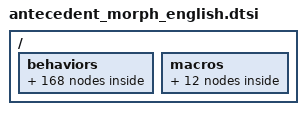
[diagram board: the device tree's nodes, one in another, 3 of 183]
// English schema version v2.0
// Automatically generated by Antecedent Morph Configurator

/ {
    behaviors {
        // Mod-Morphs
        // Base layer
        // NE
        amenneagm: amenneagm {
            compatible = "zmk,behavior-mod-morph";
            #binding-cells = <0>;
            bindings = <&amennea>, <&amenneg>;
            mods = <(MOD_LGUI)>;
        };
        amennecagm: amennecagm {
            compatible = "zmk,behavior-mod-morph";
            #binding-cells = <0>;
            bindings = <&amennec>, <&amenneagm>;
            mods = <(MOD_LALT|MOD_LGUI)>;
        };
        amennem: amennem {
            compatible = "zmk,behavior-mod-morph";
            #binding-cells = <0>;
            bindings = <&amenne>, <&amennecagm>;
            mods = <(MOD_LCTL|MOD_LALT|MOD_LGUI)>;
        };
        // E
        ameneagm: ameneagm {
            compatible = "zmk,behavior-mod-morph";
            #binding-cells = <0>;
            bindings = <&amenea>, <&ameneg>;
            mods = <(MOD_LGUI)>;
        };
        amenecagm: amenecagm {
            compatible = "zmk,behavior-mod-morph";
            #binding-cells = <0>;
            bindings = <&amenec>, <&ameneagm>;
            mods = <(MOD_LALT|MOD_LGUI)>;
        };
        amenem: amenem {
            compatible = "zmk,behavior-mod-morph";
            #binding-cells = <0>;
            bindings = <&amene>, <&amenecagm>;
            mods = <(MOD_LCTL|MOD_LALT|MOD_LGUI)>;
        };
        // SE
        amenseagm: amenseagm {
            compatible = "zmk,behavior-mod-morph";
            #binding-cells = <0>;
            bindings = <&amensea>, <&amenseg>;
            mods = <(MOD_LGUI)>;
        };
        amensecagm: amensecagm {
            compatible = "zmk,behavior-mod-morph";
            #binding-cells = <0>;
            bindings = <&amensec>, <&amenseagm>;
            mods = <(MOD_LALT|MOD_LGUI)>;
        };
        amensem: amensem {
            compatible = "zmk,behavior-mod-morph";
            #binding-cells = <0>;
            bindings = <&amense>, <&amensecagm>;
            mods = <(MOD_LCTL|MOD_LALT|MOD_LGUI)>;
        };
        // NW
        amennwagm: amennwagm {
            compatible = "zmk,behavior-mod-morph";
            #binding-cells = <0>;
            bindings = <&amennwa>, <&amennwg>;
            mods = <(MOD_RGUI)>;
        };
        amennwcagm: amennwcagm {
            compatible = "zmk,behavior-mod-morph";
            #binding-cells = <0>;
            bindings = <&amennwc>, <&amennwagm>;
            mods = <(MOD_RALT|MOD_RGUI)>;
        };
        amennwm: amennwm {
            compatible = "zmk,behavior-mod-morph";
            #binding-cells = <0>;
            bindings = <&amennw>, <&amennwcagm>;
            mods = <(MOD_RCTL|MOD_RALT|MOD_RGUI)>;
        };
        // W
        amenwagm: amenwagm {
            compatible = "zmk,behavior-mod-morph";
            #binding-cells = <0>;
            bindings = <&amenwa>, <&amenwg>;
            mods = <(MOD_RGUI)>;
        };
        amenwcagm: amenwcagm {
            compatible = "zmk,behavior-mod-morph";
            #binding-cells = <0>;
            bindings = <&amenwc>, <&amenwagm>;
            mods = <(MOD_RALT|MOD_RGUI)>;
        };
        amenwm: amenwm {
            compatible = "zmk,behavior-mod-morph";
            #binding-cells = <0>;
            bindings = <&amenw>, <&amenwcagm>;
            mods = <(MOD_RCTL|MOD_RALT|MOD_RGUI)>;
        };
        // SW
        amenswagm: amenswagm {
            compatible = "zmk,behavior-mod-morph";
            #binding-cells = <0>;
            bindings = <&amenswa>, <&amenswg>;
            mods = <(MOD_RGUI)>;
        };
        amenswcagm: amenswcagm {
            compatible = "zmk,behavior-mod-morph";
            #binding-cells = <0>;
            bindings = <&amenswc>, <&amenswagm>;
            mods = <(MOD_RALT|MOD_RGUI)>;
        };
        amenswm: amenswm {
            compatible = "zmk,behavior-mod-morph";
            #binding-cells = <0>;
            bindings = <&amensw>, <&amenswcagm>;
            mods = <(MOD_RCTL|MOD_RALT|MOD_RGUI)>;
        };
        // Mouse layer
        // NE
        amenmosneagm: amenmosneagm {
            compatible = "zmk,behavior-mod-morph";
            #binding-cells = <0>;
            bindings = <&amenmosnea>, <&amenmosneg>;
            mods = <(MOD_LGUI)>;
        };
        amenmosnecagm: amenmosnecagm {
            compatible = "zmk,behavior-mod-morph";
            #binding-cells = <0>;
            bindings = <&amenmosnec>, <&amenmosneagm>;
            mods = <(MOD_LALT|MOD_LGUI)>;
        };
        amenmosnem: amenmosnem {
            compatible = "zmk,behavior-mod-morph";
            #binding-cells = <0>;
            bindings = <&amenmosne>, <&amenmosnecagm>;
            mods = <(MOD_LCTL|MOD_LALT|MOD_LGUI)>;
        };
        // E
        amenmoseagm: amenmoseagm {
            compatible = "zmk,behavior-mod-morph";
            #binding-cells = <0>;
            bindings = <&amenmosea>, <&amenmoseg>;
            mods = <(MOD_LGUI)>;
        };
        amenmosecagm: amenmosecagm {
            compatible = "zmk,behavior-mod-morph";
            #binding-cells = <0>;
            bindings = <&amenmosec>, <&amenmoseagm>;
            mods = <(MOD_LALT|MOD_LGUI)>;
        };
        amenmosem: amenmosem {
            compatible = "zmk,behavior-mod-morph";
            #binding-cells = <0>;
            bindings = <&amenmose>, <&amenmosecagm>;
            mods = <(MOD_LCTL|MOD_LALT|MOD_LGUI)>;
        };
        // SE
        amenmosseagm: amenmosseagm {
            compatible = "zmk,behavior-mod-morph";
            #binding-cells = <0>;
            bindings = <&amenmossea>, <&amenmosseg>;
            mods = <(MOD_LGUI)>;
        };
        amenmossecagm: amenmossecagm {
            compatible = "zmk,behavior-mod-morph";
            #binding-cells = <0>;
            bindings = <&amenmossec>, <&amenmosseagm>;
            mods = <(MOD_LALT|MOD_LGUI)>;
        };
        amenmossem: amenmossem {
            compatible = "zmk,behavior-mod-morph";
            #binding-cells = <0>;
            bindings = <&amenmosse>, <&amenmossecagm>;
            mods = <(MOD_LCTL|MOD_LALT|MOD_LGUI)>;
        };
        // Navigation layer
        // NE
        amennavneagm: amennavneagm {
            compatible = "zmk,behavior-mod-morph";
            #binding-cells = <0>;
            bindings = <&amennavnea>, <&amennavneg>;
            mods = <(MOD_LGUI)>;
        };
        amennavnecagm: amennavnecagm {
            compatible = "zmk,behavior-mod-morph";
            #binding-cells = <0>;
            bindings = <&amennavnec>, <&amennavneagm>;
            mods = <(MOD_LALT|MOD_LGUI)>;
        };
        amennavnem: amennavnem {
            compatible = "zmk,behavior-mod-morph";
            #binding-cells = <0>;
            bindings = <&amennavne>, <&amennavnecagm>;
            mods = <(MOD_LCTL|MOD_LALT|MOD_LGUI)>;
        };
        // E
        amennaveagm: amennaveagm {
            compatible = "zmk,behavior-mod-morph";
            #binding-cells = <0>;
            bindings = <&amennavea>, <&amennaveg>;
            mods = <(MOD_LGUI)>;
        };
        amennavecagm: amennavecagm {
            compatible = "zmk,behavior-mod-morph";
            #binding-cells = <0>;
            bindings = <&amennavec>, <&amennaveagm>;
            mods = <(MOD_LALT|MOD_LGUI)>;
        };
        amennavem: amennavem {
            compatible = "zmk,behavior-mod-morph";
            #binding-cells = <0>;
            bindings = <&amennave>, <&amennavecagm>;
            mods = <(MOD_LCTL|MOD_LALT|MOD_LGUI)>;
        };
        // SE
        amennavseagm: amennavseagm {
            compatible = "zmk,behavior-mod-morph";
            #binding-cells = <0>;
            bindings = <&amennavsea>, <&amennavseg>;
            mods = <(MOD_LGUI)>;
        };
        amennavsecagm: amennavsecagm {
            compatible = "zmk,behavior-mod-morph";
            #binding-cells = <0>;
            bindings = <&amennavsec>, <&amennavseagm>;
            mods = <(MOD_LALT|MOD_LGUI)>;
        };
        amennavsem: amennavsem {
            compatible = "zmk,behavior-mod-morph";
            #binding-cells = <0>;
            bindings = <&amennavse>, <&amennavsecagm>;
            mods = <(MOD_LCTL|MOD_LALT|MOD_LGUI)>;
        };
        // Media layer
        // NE
        amenmedneagm: amenmedneagm {
            compatible = "zmk,behavior-mod-morph";
            #binding-cells = <0>;
            bindings = <&amenmednea>, <&amenmedneg>;
            mods = <(MOD_LGUI)>;
        };
        amenmednecagm: amenmednecagm {
            compatible = "zmk,behavior-mod-morph";
            #binding-cells = <0>;
            bindings = <&amenmednec>, <&amenmedneagm>;
            mods = <(MOD_LALT|MOD_LGUI)>;
        };
        amenmednem: amenmednem {
            compatible = "zmk,behavior-mod-morph";
            #binding-cells = <0>;
            bindings = <&amenmedne>, <&amenmednecagm>;
            mods = <(MOD_LCTL|MOD_LALT|MOD_LGUI)>;
        };
        // E
        amenmedeagm: amenmedeagm {
            compatible = "zmk,behavior-mod-morph";
            #binding-cells = <0>;
            bindings = <&amenmedea>, <&amenmedeg>;
            mods = <(MOD_LGUI)>;
        };
        amenmedecagm: amenmedecagm {
            compatible = "zmk,behavior-mod-morph";
            #binding-cells = <0>;
            bindings = <&amenmedec>, <&amenmedeagm>;
            mods = <(MOD_LALT|MOD_LGUI)>;
        };
        amenmedem: amenmedem {
            compatible = "zmk,behavior-mod-morph";
            #binding-cells = <0>;
            bindings = <&amenmede>, <&amenmedecagm>;
            mods = <(MOD_LCTL|MOD_LALT|MOD_LGUI)>;
        };
        // SE
        amenmedseagm: amenmedseagm {
            compatible = "zmk,behavior-mod-morph";
            #binding-cells = <0>;
            bindings = <&amenmedsea>, <&amenmedseg>;
            mods = <(MOD_LGUI)>;
        };
        amenmedsecagm: amenmedsecagm {
            compatible = "zmk,behavior-mod-morph";
            #binding-cells = <0>;
            bindings = <&amenmedsec>, <&amenmedseagm>;
            mods = <(MOD_LALT|MOD_LGUI)>;
        };
        amenmedsem: amenmedsem {
            compatible = "zmk,behavior-mod-morph";
            #binding-cells = <0>;
            bindings = <&amenmedse>, <&amenmedsecagm>;
            mods = <(MOD_LCTL|MOD_LALT|MOD_LGUI)>;
        };
        // Symbol layer
        // NW
        amensymnwagm: amensymnwagm {
            compatible = "zmk,behavior-mod-morph";
            #binding-cells = <0>;
            bindings = <&amensymnwa>, <&amensymnwg>;
            mods = <(MOD_RGUI)>;
        };
        amensymnwcagm: amensymnwcagm {
            compatible = "zmk,behavior-mod-morph";
            #binding-cells = <0>;
            bindings = <&amensymnwc>, <&amensymnwagm>;
            mods = <(MOD_RALT|MOD_RGUI)>;
        };
        amensymnwm: amensymnwm {
            compatible = "zmk,behavior-mod-morph";
            #binding-cells = <0>;
            bindings = <&amensymnw>, <&amensymnwcagm>;
            mods = <(MOD_RCTL|MOD_RALT|MOD_RGUI)>;
        };
        // W
        amensymwagm: amensymwagm {
            compatible = "zmk,behavior-mod-morph";
            #binding-cells = <0>;
            bindings = <&amensymwa>, <&amensymwg>;
            mods = <(MOD_RGUI)>;
        };
        amensymwcagm: amensymwcagm {
            compatible = "zmk,behavior-mod-morph";
            #binding-cells = <0>;
            bindings = <&amensymwc>, <&amensymwagm>;
            mods = <(MOD_RALT|MOD_RGUI)>;
        };
        amensymwm: amensymwm {
            compatible = "zmk,behavior-mod-morph";
            #binding-cells = <0>;
            bindings = <&amensymw>, <&amensymwcagm>;
            mods = <(MOD_RCTL|MOD_RALT|MOD_RGUI)>;
        };
        // SW
        amensymswagm: amensymswagm {
            compatible = "zmk,behavior-mod-morph";
            #binding-cells = <0>;
            bindings = <&amensymswa>, <&amensymswg>;
            mods = <(MOD_RGUI)>;
        };
        amensymswcagm: amensymswcagm {
            compatible = "zmk,behavior-mod-morph";
            #binding-cells = <0>;
            bindings = <&amensymswc>, <&amensymswagm>;
            mods = <(MOD_RALT|MOD_RGUI)>;
        };
        amensymswm: amensymswm {
            compatible = "zmk,behavior-mod-morph";
            #binding-cells = <0>;
            bindings = <&amensymsw>, <&amensymswcagm>;
            mods = <(MOD_RCTL|MOD_RALT|MOD_RGUI)>;
        };
        // Number layer
        // NW
        amennumnwagm: amennumnwagm {
            compatible = "zmk,behavior-mod-morph";
            #binding-cells = <0>;
            bindings = <&amennumnwa>, <&amennumnwg>;
            mods = <(MOD_RGUI)>;
        };
        amennumnwcagm: amennumnwcagm {
            compatible = "zmk,behavior-mod-morph";
            #binding-cells = <0>;
            bindings = <&amennumnwc>, <&amennumnwagm>;
            mods = <(MOD_RALT|MOD_RGUI)>;
        };
        amennumnwm: amennumnwm {
            compatible = "zmk,behavior-mod-morph";
            #binding-cells = <0>;
            bindings = <&amennumnw>, <&amennumnwcagm>;
            mods = <(MOD_RCTL|MOD_RALT|MOD_RGUI)>;
        };
        // W
        amennumwagm: amennumwagm {
            compatible = "zmk,behavior-mod-morph";
            #binding-cells = <0>;
            bindings = <&amennumwa>, <&amennumwg>;
            mods = <(MOD_RGUI)>;
        };
        amennumwcagm: amennumwcagm {
            compatible = "zmk,behavior-mod-morph";
            #binding-cells = <0>;
            bindings = <&amennumwc>, <&amennumwagm>;
            mods = <(MOD_RALT|MOD_RGUI)>;
        };
        amennumwm: amennumwm {
            compatible = "zmk,behavior-mod-morph";
            #binding-cells = <0>;
            bindings = <&amennumw>, <&amennumwcagm>;
            mods = <(MOD_RCTL|MOD_RALT|MOD_RGUI)>;
        };
        // SW
        amennumswagm: amennumswagm {
            compatible = "zmk,behavior-mod-morph";
            #binding-cells = <0>;
            bindings = <&amennumswa>, <&amennumswg>;
            mods = <(MOD_RGUI)>;
        };
        amennumswcagm: amennumswcagm {
            compatible = "zmk,behavior-mod-morph";
            #binding-cells = <0>;
            bindings = <&amennumswc>, <&amennumswagm>;
            mods = <(MOD_RALT|MOD_RGUI)>;
        };
        amennumswm: amennumswm {
            compatible = "zmk,behavior-mod-morph";
            #binding-cells = <0>;
            bindings = <&amennumsw>, <&amennumswcagm>;
            mods = <(MOD_RCTL|MOD_RALT|MOD_RGUI)>;
        };
        // Function layer
        // NW
        amenfunnwagm: amenfunnwagm {
            compatible = "zmk,behavior-mod-morph";
            #binding-cells = <0>;
            bindings = <&amenfunnwa>, <&amenfunnwg>;
            mods = <(MOD_RGUI)>;
        };
        amenfunnwcagm: amenfunnwcagm {
            compatible = "zmk,behavior-mod-morph";
            #binding-cells = <0>;
            bindings = <&amenfunnwc>, <&amenfunnwagm>;
            mods = <(MOD_RALT|MOD_RGUI)>;
        };
        amenfunnwm: amenfunnwm {
            compatible = "zmk,behavior-mod-morph";
            #binding-cells = <0>;
            bindings = <&amenfunnw>, <&amenfunnwcagm>;
            mods = <(MOD_RCTL|MOD_RALT|MOD_RGUI)>;
        };
        // W
        amenfunwagm: amenfunwagm {
            compatible = "zmk,behavior-mod-morph";
            #binding-cells = <0>;
            bindings = <&amenfunwa>, <&amenfunwg>;
            mods = <(MOD_RGUI)>;
        };
        amenfunwcagm: amenfunwcagm {
            compatible = "zmk,behavior-mod-morph";
            #binding-cells = <0>;
            bindings = <&amenfunwc>, <&amenfunwagm>;
            mods = <(MOD_RALT|MOD_RGUI)>;
        };
        amenfunwm: amenfunwm {
            compatible = "zmk,behavior-mod-morph";
            #binding-cells = <0>;
            bindings = <&amenfunw>, <&amenfunwcagm>;
            mods = <(MOD_RCTL|MOD_RALT|MOD_RGUI)>;
        };
        // SW
        amenfunswagm: amenfunswagm {
            compatible = "zmk,behavior-mod-morph";
            #binding-cells = <0>;
            bindings = <&amenfunswa>, <&amenfunswg>;
            mods = <(MOD_RGUI)>;
        };
        amenfunswcagm: amenfunswcagm {
            compatible = "zmk,behavior-mod-morph";
            #binding-cells = <0>;
            bindings = <&amenfunswc>, <&amenfunswagm>;
            mods = <(MOD_RALT|MOD_RGUI)>;
        };
        amenfunswm: amenfunswm {
            compatible = "zmk,behavior-mod-morph";
            #binding-cells = <0>;
            bindings = <&amenfunsw>, <&amenfunswcagm>;
            mods = <(MOD_RCTL|MOD_RALT|MOD_RGUI)>;
        };
        // Antecedent Morphs
        amenne: am_en_ne {
            compatible = "zmk,behavior-antecedent-morph";
            label = "AM_EN_NE";
            #binding-cells = <0>;
            defaults = <&none>;
            bindings = <&amen_prokofyevme>;
            antecedents = <AT>;
            max-delay-ms = <U_ANTMORPH_DELAY>;
        };
        amennec: am_en_ne_c {
            compatible = "zmk,behavior-antecedent-morph";
            label = "AM_EN_NE_C";
            #binding-cells = <0>;
            defaults = <&none>;
            bindings = <&none>;
            antecedents = <0x070100>;
            max-delay-ms = <U_ANTMORPH_DELAY>;
        };
        amennea: am_en_ne_a {
            compatible = "zmk,behavior-antecedent-morph";
            label = "AM_EN_NE_A";
            #binding-cells = <0>;
            defaults = <&none>;
            bindings = <&none>;
            antecedents = <0x070100>;
            max-delay-ms = <U_ANTMORPH_DELAY>;
        };
        amenneg: am_en_ne_g {
            compatible = "zmk,behavior-antecedent-morph";
            label = "AM_EN_NE_G";
            #binding-cells = <0>;
            defaults = <&none>;
            bindings = <&none>;
            antecedents = <0x070100>;
            max-delay-ms = <U_ANTMORPH_DELAY>;
        };
        amene: am_en_e {
            compatible = "zmk,behavior-antecedent-morph";
            label = "AM_EN_E";
            #binding-cells = <0>;
            defaults = <&none>;
            bindings = <&amen_proostas>, <&amen_monday>, <&amen_tuesday>, <&amen_wednesday>, <&amen_thursday>, <&amen_friday>, <&amen_saturday>, <&amen_sunday>, <&amen_yandexru>, <&amen_english_v20>;
            antecedents = <P N1 N2 N3 N4 N5 N6 N7 AT SPACE>;
            max-delay-ms = <U_ANTMORPH_DELAY>;
        };
        amenec: am_en_e_c {
            compatible = "zmk,behavior-antecedent-morph";
            label = "AM_EN_E_C";
            #binding-cells = <0>;
            defaults = <&none>;
            bindings = <&none>;
            antecedents = <0x070100>;
            max-delay-ms = <U_ANTMORPH_DELAY>;
        };
        amenea: am_en_e_a {
            compatible = "zmk,behavior-antecedent-morph";
            label = "AM_EN_E_A";
            #binding-cells = <0>;
            defaults = <&none>;
            bindings = <&none>;
            antecedents = <0x070100>;
            max-delay-ms = <U_ANTMORPH_DELAY>;
        };
        ameneg: am_en_e_g {
            compatible = "zmk,behavior-antecedent-morph";
            label = "AM_EN_E_G";
            #binding-cells = <0>;
            defaults = <&none>;
            bindings = <&none>;
            antecedents = <0x070100>;
            max-delay-ms = <U_ANTMORPH_DELAY>;
        };
        amense: am_en_se {
            compatible = "zmk,behavior-antecedent-morph";
            label = "AM_EN_SE";
            #binding-cells = <0>;
            defaults = <&none>;
            bindings = <&amen_gmailcom>;
            antecedents = <AT>;
            max-delay-ms = <U_ANTMORPH_DELAY>;
        };
        amensec: am_en_se_c {
            compatible = "zmk,behavior-antecedent-morph";
            label = "AM_EN_SE_C";
            #binding-cells = <0>;
            defaults = <&none>;
            bindings = <&none>;
            antecedents = <0x070100>;
            max-delay-ms = <U_ANTMORPH_DELAY>;
        };
        amensea: am_en_se_a {
            compatible = "zmk,behavior-antecedent-morph";
            label = "AM_EN_SE_A";
            #binding-cells = <0>;
            defaults = <&none>;
            bindings = <&none>;
            antecedents = <0x070100>;
            max-delay-ms = <U_ANTMORPH_DELAY>;
        };
        amenseg: am_en_se_g {
            compatible = "zmk,behavior-antecedent-morph";
            label = "AM_EN_SE_G";
            #binding-cells = <0>;
            defaults = <&none>;
            bindings = <&none>;
            antecedents = <0x070100>;
            max-delay-ms = <U_ANTMORPH_DELAY>;
        };
        amennw: am_en_nw {
            compatible = "zmk,behavior-antecedent-morph";
            label = "AM_EN_NW";
            #binding-cells = <0>;
            defaults = <&none>;
            bindings = <&none>;
            antecedents = <0x070100>;
            max-delay-ms = <U_ANTMORPH_DELAY>;
        };
        amennwc: am_en_nw_c {
            compatible = "zmk,behavior-antecedent-morph";
            label = "AM_EN_NW_C";
            #binding-cells = <0>;
            defaults = <&none>;
            bindings = <&none>;
            antecedents = <0x070100>;
            max-delay-ms = <U_ANTMORPH_DELAY>;
        };
        amennwa: am_en_nw_a {
            compatible = "zmk,behavior-antecedent-morph";
            label = "AM_EN_NW_A";
            #binding-cells = <0>;
            defaults = <&none>;
            bindings = <&none>;
            antecedents = <0x070100>;
            max-delay-ms = <U_ANTMORPH_DELAY>;
        };
        amennwg: am_en_nw_g {
            compatible = "zmk,behavior-antecedent-morph";
            label = "AM_EN_NW_G";
            #binding-cells = <0>;
            defaults = <&none>;
            bindings = <&none>;
            antecedents = <0x070100>;
            max-delay-ms = <U_ANTMORPH_DELAY>;
        };
        amenw: am_en_w {
            compatible = "zmk,behavior-antecedent-morph";
            label = "AM_EN_W";
            #binding-cells = <0>;
            defaults = <&none>;
            bindings = <&none>;
            antecedents = <0x070100>;
            max-delay-ms = <U_ANTMORPH_DELAY>;
        };
        amenwc: am_en_w_c {
            compatible = "zmk,behavior-antecedent-morph";
            label = "AM_EN_W_C";
            #binding-cells = <0>;
            defaults = <&none>;
            bindings = <&none>;
            antecedents = <0x070100>;
            max-delay-ms = <U_ANTMORPH_DELAY>;
        };
        amenwa: am_en_w_a {
            compatible = "zmk,behavior-antecedent-morph";
            label = "AM_EN_W_A";
            #binding-cells = <0>;
            defaults = <&none>;
            bindings = <&none>;
            antecedents = <0x070100>;
            max-delay-ms = <U_ANTMORPH_DELAY>;
        };
        amenwg: am_en_w_g {
            compatible = "zmk,behavior-antecedent-morph";
            label = "AM_EN_W_G";
            #binding-cells = <0>;
            defaults = <&none>;
            bindings = <&none>;
            antecedents = <0x070100>;
            max-delay-ms = <U_ANTMORPH_DELAY>;
        };
        amensw: am_en_sw {
            compatible = "zmk,behavior-antecedent-morph";
            label = "AM_EN_SW";
            #binding-cells = <0>;
            defaults = <&none>;
            bindings = <&none>;
            antecedents = <0x070100>;
            max-delay-ms = <U_ANTMORPH_DELAY>;
        };
        amenswc: am_en_sw_c {
            compatible = "zmk,behavior-antecedent-morph";
            label = "AM_EN_SW_C";
            #binding-cells = <0>;
            defaults = <&none>;
            bindings = <&none>;
            antecedents = <0x070100>;
            max-delay-ms = <U_ANTMORPH_DELAY>;
        };
        amenswa: am_en_sw_a {
            compatible = "zmk,behavior-antecedent-morph";
            label = "AM_EN_SW_A";
            #binding-cells = <0>;
            defaults = <&none>;
            bindings = <&none>;
            antecedents = <0x070100>;
            max-delay-ms = <U_ANTMORPH_DELAY>;
        };
        amenswg: am_en_sw_g {
            compatible = "zmk,behavior-antecedent-morph";
            label = "AM_EN_SW_G";
            #binding-cells = <0>;
            defaults = <&none>;
            bindings = <&none>;
            antecedents = <0x070100>;
            max-delay-ms = <U_ANTMORPH_DELAY>;
        };
        amenmosne: am_en_mos_ne {
            compatible = "zmk,behavior-antecedent-morph";
            label = "AM_EN_MOS_NE";
            #binding-cells = <0>;
            defaults = <&none>;
            bindings = <&none>;
            antecedents = <0x070100>;
            max-delay-ms = <U_ANTMORPH_DELAY>;
        };
        amenmosnec: am_en_mos_ne_c {
            compatible = "zmk,behavior-antecedent-morph";
            label = "AM_EN_MOS_NE_C";
            #binding-cells = <0>;
            defaults = <&none>;
            bindings = <&none>;
            antecedents = <0x070100>;
            max-delay-ms = <U_ANTMORPH_DELAY>;
        };
        amenmosnea: am_en_mos_ne_a {
            compatible = "zmk,behavior-antecedent-morph";
            label = "AM_EN_MOS_NE_A";
            #binding-cells = <0>;
            defaults = <&none>;
            bindings = <&none>;
            antecedents = <0x070100>;
            max-delay-ms = <U_ANTMORPH_DELAY>;
        };
        amenmosneg: am_en_mos_ne_g {
            compatible = "zmk,behavior-antecedent-morph";
            label = "AM_EN_MOS_NE_G";
            #binding-cells = <0>;
            defaults = <&none>;
            bindings = <&none>;
            antecedents = <0x070100>;
            max-delay-ms = <U_ANTMORPH_DELAY>;
        };
        amenmose: am_en_mos_e {
            compatible = "zmk,behavior-antecedent-morph";
            label = "AM_EN_MOS_E";
            #binding-cells = <0>;
            defaults = <&none>;
            bindings = <&none>;
            antecedents = <0x070100>;
            max-delay-ms = <U_ANTMORPH_DELAY>;
        };
        amenmosec: am_en_mos_e_c {
            compatible = "zmk,behavior-antecedent-morph";
            label = "AM_EN_MOS_E_C";
            #binding-cells = <0>;
            defaults = <&none>;
            bindings = <&none>;
            antecedents = <0x070100>;
            max-delay-ms = <U_ANTMORPH_DELAY>;
        };
        amenmosea: am_en_mos_e_a {
            compatible = "zmk,behavior-antecedent-morph";
            label = "AM_EN_MOS_E_A";
            #binding-cells = <0>;
            defaults = <&none>;
            bindings = <&none>;
            antecedents = <0x070100>;
            max-delay-ms = <U_ANTMORPH_DELAY>;
        };
        amenmoseg: am_en_mos_e_g {
            compatible = "zmk,behavior-antecedent-morph";
            label = "AM_EN_MOS_E_G";
            #binding-cells = <0>;
            defaults = <&none>;
            bindings = <&none>;
            antecedents = <0x070100>;
            max-delay-ms = <U_ANTMORPH_DELAY>;
        };
        amenmosse: am_en_mos_se {
            compatible = "zmk,behavior-antecedent-morph";
            label = "AM_EN_MOS_SE";
            #binding-cells = <0>;
            defaults = <&none>;
            bindings = <&none>;
            antecedents = <0x070100>;
            max-delay-ms = <U_ANTMORPH_DELAY>;
        };
        amenmossec: am_en_mos_se_c {
            compatible = "zmk,behavior-antecedent-morph";
            label = "AM_EN_MOS_SE_C";
            #binding-cells = <0>;
            defaults = <&none>;
            bindings = <&none>;
            antecedents = <0x070100>;
            max-delay-ms = <U_ANTMORPH_DELAY>;
        };
        amenmossea: am_en_mos_se_a {
            compatible = "zmk,behavior-antecedent-morph";
            label = "AM_EN_MOS_SE_A";
            #binding-cells = <0>;
            defaults = <&none>;
            bindings = <&none>;
            antecedents = <0x070100>;
            max-delay-ms = <U_ANTMORPH_DELAY>;
        };
        amenmosseg: am_en_mos_se_g {
            compatible = "zmk,behavior-antecedent-morph";
            label = "AM_EN_MOS_SE_G";
            #binding-cells = <0>;
            defaults = <&none>;
            bindings = <&none>;
            antecedents = <0x070100>;
            max-delay-ms = <U_ANTMORPH_DELAY>;
        };
        amennavne: am_en_nav_ne {
            compatible = "zmk,behavior-antecedent-morph";
            label = "AM_EN_NAV_NE";
            #binding-cells = <0>;
            defaults = <&none>;
            bindings = <&none>;
            antecedents = <0x070100>;
            max-delay-ms = <U_ANTMORPH_DELAY>;
        };
        amennavnec: am_en_nav_ne_c {
            compatible = "zmk,behavior-antecedent-morph";
            label = "AM_EN_NAV_NE_C";
            #binding-cells = <0>;
            defaults = <&none>;
            bindings = <&none>;
            antecedents = <0x070100>;
            max-delay-ms = <U_ANTMORPH_DELAY>;
        };
        amennavnea: am_en_nav_ne_a {
            compatible = "zmk,behavior-antecedent-morph";
            label = "AM_EN_NAV_NE_A";
            #binding-cells = <0>;
            defaults = <&none>;
            bindings = <&none>;
            antecedents = <0x070100>;
            max-delay-ms = <U_ANTMORPH_DELAY>;
        };
        amennavneg: am_en_nav_ne_g {
            compatible = "zmk,behavior-antecedent-morph";
            label = "AM_EN_NAV_NE_G";
            #binding-cells = <0>;
            defaults = <&none>;
            bindings = <&none>;
            antecedents = <0x070100>;
            max-delay-ms = <U_ANTMORPH_DELAY>;
        };
        amennave: am_en_nav_e {
            compatible = "zmk,behavior-antecedent-morph";
            label = "AM_EN_NAV_E";
            #binding-cells = <0>;
            defaults = <&none>;
            bindings = <&none>;
            antecedents = <0x070100>;
            max-delay-ms = <U_ANTMORPH_DELAY>;
        };
        amennavec: am_en_nav_e_c {
            compatible = "zmk,behavior-antecedent-morph";
            label = "AM_EN_NAV_E_C";
            #binding-cells = <0>;
            defaults = <&none>;
            bindings = <&none>;
            antecedents = <0x070100>;
            max-delay-ms = <U_ANTMORPH_DELAY>;
        };
        amennavea: am_en_nav_e_a {
            compatible = "zmk,behavior-antecedent-morph";
            label = "AM_EN_NAV_E_A";
            #binding-cells = <0>;
            defaults = <&none>;
            bindings = <&none>;
            antecedents = <0x070100>;
            max-delay-ms = <U_ANTMORPH_DELAY>;
        };
        amennaveg: am_en_nav_e_g {
            compatible = "zmk,behavior-antecedent-morph";
            label = "AM_EN_NAV_E_G";
            #binding-cells = <0>;
            defaults = <&none>;
            bindings = <&none>;
            antecedents = <0x070100>;
            max-delay-ms = <U_ANTMORPH_DELAY>;
        };
        amennavse: am_en_nav_se {
            compatible = "zmk,behavior-antecedent-morph";
            label = "AM_EN_NAV_SE";
            #binding-cells = <0>;
            defaults = <&none>;
            bindings = <&none>;
            antecedents = <0x070100>;
            max-delay-ms = <U_ANTMORPH_DELAY>;
        };
        amennavsec: am_en_nav_se_c {
            compatible = "zmk,behavior-antecedent-morph";
            label = "AM_EN_NAV_SE_C";
            #binding-cells = <0>;
            defaults = <&none>;
            bindings = <&none>;
            antecedents = <0x070100>;
            max-delay-ms = <U_ANTMORPH_DELAY>;
        };
        amennavsea: am_en_nav_se_a {
            compatible = "zmk,behavior-antecedent-morph";
            label = "AM_EN_NAV_SE_A";
            #binding-cells = <0>;
            defaults = <&none>;
            bindings = <&none>;
            antecedents = <0x070100>;
            max-delay-ms = <U_ANTMORPH_DELAY>;
        };
        amennavseg: am_en_nav_se_g {
            compatible = "zmk,behavior-antecedent-morph";
            label = "AM_EN_NAV_SE_G";
            #binding-cells = <0>;
            defaults = <&none>;
            bindings = <&none>;
            antecedents = <0x070100>;
            max-delay-ms = <U_ANTMORPH_DELAY>;
        };
        amenmedne: am_en_med_ne {
            compatible = "zmk,behavior-antecedent-morph";
            label = "AM_EN_MED_NE";
            #binding-cells = <0>;
            defaults = <&none>;
            bindings = <&none>;
            antecedents = <0x070100>;
            max-delay-ms = <U_ANTMORPH_DELAY>;
        };
        amenmednec: am_en_med_ne_c {
            compatible = "zmk,behavior-antecedent-morph";
            label = "AM_EN_MED_NE_C";
            #binding-cells = <0>;
            defaults = <&none>;
            bindings = <&none>;
            antecedents = <0x070100>;
            max-delay-ms = <U_ANTMORPH_DELAY>;
        };
        amenmednea: am_en_med_ne_a {
            compatible = "zmk,behavior-antecedent-morph";
            label = "AM_EN_MED_NE_A";
            #binding-cells = <0>;
            defaults = <&none>;
            bindings = <&none>;
            antecedents = <0x070100>;
            max-delay-ms = <U_ANTMORPH_DELAY>;
        };
        amenmedneg: am_en_med_ne_g {
            compatible = "zmk,behavior-antecedent-morph";
            label = "AM_EN_MED_NE_G";
            #binding-cells = <0>;
            defaults = <&none>;
            bindings = <&none>;
            antecedents = <0x070100>;
            max-delay-ms = <U_ANTMORPH_DELAY>;
        };
        amenmede: am_en_med_e {
            compatible = "zmk,behavior-antecedent-morph";
            label = "AM_EN_MED_E";
            #binding-cells = <0>;
            defaults = <&none>;
            bindings = <&none>;
            antecedents = <0x070100>;
            max-delay-ms = <U_ANTMORPH_DELAY>;
        };
        amenmedec: am_en_med_e_c {
            compatible = "zmk,behavior-antecedent-morph";
            label = "AM_EN_MED_E_C";
            #binding-cells = <0>;
            defaults = <&none>;
            bindings = <&none>;
            antecedents = <0x070100>;
            max-delay-ms = <U_ANTMORPH_DELAY>;
        };
        amenmedea: am_en_med_e_a {
            compatible = "zmk,behavior-antecedent-morph";
            label = "AM_EN_MED_E_A";
            #binding-cells = <0>;
            defaults = <&none>;
            bindings = <&none>;
            antecedents = <0x070100>;
            max-delay-ms = <U_ANTMORPH_DELAY>;
        };
        amenmedeg: am_en_med_e_g {
            compatible = "zmk,behavior-antecedent-morph";
            label = "AM_EN_MED_E_G";
            #binding-cells = <0>;
            defaults = <&none>;
            bindings = <&none>;
            antecedents = <0x070100>;
            max-delay-ms = <U_ANTMORPH_DELAY>;
        };
        amenmedse: am_en_med_se {
            compatible = "zmk,behavior-antecedent-morph";
            label = "AM_EN_MED_SE";
            #binding-cells = <0>;
            defaults = <&none>;
            bindings = <&none>;
            antecedents = <0x070100>;
            max-delay-ms = <U_ANTMORPH_DELAY>;
        };
        amenmedsec: am_en_med_se_c {
            compatible = "zmk,behavior-antecedent-morph";
            label = "AM_EN_MED_SE_C";
            #binding-cells = <0>;
            defaults = <&none>;
            bindings = <&none>;
            antecedents = <0x070100>;
            max-delay-ms = <U_ANTMORPH_DELAY>;
        };
        amenmedsea: am_en_med_se_a {
            compatible = "zmk,behavior-antecedent-morph";
            label = "AM_EN_MED_SE_A";
            #binding-cells = <0>;
            defaults = <&none>;
            bindings = <&none>;
            antecedents = <0x070100>;
            max-delay-ms = <U_ANTMORPH_DELAY>;
        };
        amenmedseg: am_en_med_se_g {
            compatible = "zmk,behavior-antecedent-morph";
            label = "AM_EN_MED_SE_G";
            #binding-cells = <0>;
            defaults = <&none>;
            bindings = <&none>;
            antecedents = <0x070100>;
            max-delay-ms = <U_ANTMORPH_DELAY>;
        };
        amenfunnw: am_en_fun_nw {
            compatible = "zmk,behavior-antecedent-morph";
            label = "AM_EN_FUN_NW";
            #binding-cells = <0>;
            defaults = <&none>;
            bindings = <&none>;
            antecedents = <0x070100>;
            max-delay-ms = <U_ANTMORPH_DELAY>;
        };
        amenfunnwc: am_en_fun_nw_c {
            compatible = "zmk,behavior-antecedent-morph";
            label = "AM_EN_FUN_NW_C";
            #binding-cells = <0>;
            defaults = <&none>;
            bindings = <&none>;
            antecedents = <0x070100>;
            max-delay-ms = <U_ANTMORPH_DELAY>;
        };
        amenfunnwa: am_en_fun_nw_a {
            compatible = "zmk,behavior-antecedent-morph";
            label = "AM_EN_FUN_NW_A";
            #binding-cells = <0>;
            defaults = <&none>;
            bindings = <&none>;
            antecedents = <0x070100>;
            max-delay-ms = <U_ANTMORPH_DELAY>;
        };
        amenfunnwg: am_en_fun_nw_g {
            compatible = "zmk,behavior-antecedent-morph";
            label = "AM_EN_FUN_NW_G";
            #binding-cells = <0>;
            defaults = <&none>;
            bindings = <&none>;
            antecedents = <0x070100>;
            max-delay-ms = <U_ANTMORPH_DELAY>;
        };
        amenfunw: am_en_fun_w {
            compatible = "zmk,behavior-antecedent-morph";
            label = "AM_EN_FUN_W";
            #binding-cells = <0>;
            defaults = <&none>;
            bindings = <&none>;
            antecedents = <0x070100>;
            max-delay-ms = <U_ANTMORPH_DELAY>;
        };
        amenfunwc: am_en_fun_w_c {
            compatible = "zmk,behavior-antecedent-morph";
            label = "AM_EN_FUN_W_C";
            #binding-cells = <0>;
            defaults = <&none>;
            bindings = <&none>;
            antecedents = <0x070100>;
            max-delay-ms = <U_ANTMORPH_DELAY>;
        };
        amenfunwa: am_en_fun_w_a {
            compatible = "zmk,behavior-antecedent-morph";
            label = "AM_EN_FUN_W_A";
            #binding-cells = <0>;
            defaults = <&none>;
            bindings = <&none>;
            antecedents = <0x070100>;
            max-delay-ms = <U_ANTMORPH_DELAY>;
        };
        amenfunwg: am_en_fun_w_g {
            compatible = "zmk,behavior-antecedent-morph";
            label = "AM_EN_FUN_W_G";
            #binding-cells = <0>;
            defaults = <&none>;
            bindings = <&none>;
            antecedents = <0x070100>;
            max-delay-ms = <U_ANTMORPH_DELAY>;
        };
        amenfunsw: am_en_fun_sw {
            compatible = "zmk,behavior-antecedent-morph";
            label = "AM_EN_FUN_SW";
            #binding-cells = <0>;
            defaults = <&none>;
            bindings = <&none>;
            antecedents = <0x070100>;
            max-delay-ms = <U_ANTMORPH_DELAY>;
        };
        amenfunswc: am_en_fun_sw_c {
            compatible = "zmk,behavior-antecedent-morph";
            label = "AM_EN_FUN_SW_C";
            #binding-cells = <0>;
            defaults = <&none>;
            bindings = <&none>;
            antecedents = <0x070100>;
            max-delay-ms = <U_ANTMORPH_DELAY>;
        };
        amenfunswa: am_en_fun_sw_a {
            compatible = "zmk,behavior-antecedent-morph";
            label = "AM_EN_FUN_SW_A";
            #binding-cells = <0>;
            defaults = <&none>;
            bindings = <&none>;
            antecedents = <0x070100>;
            max-delay-ms = <U_ANTMORPH_DELAY>;
        };
        amenfunswg: am_en_fun_sw_g {
            compatible = "zmk,behavior-antecedent-morph";
            label = "AM_EN_FUN_SW_G";
            #binding-cells = <0>;
            defaults = <&none>;
            bindings = <&none>;
            antecedents = <0x070100>;
            max-delay-ms = <U_ANTMORPH_DELAY>;
        };
        amennumnw: am_en_num_nw {
            compatible = "zmk,behavior-antecedent-morph";
            label = "AM_EN_NUM_NW";
            #binding-cells = <0>;
            defaults = <&none>;
            bindings = <&none>;
            antecedents = <0x070100>;
            max-delay-ms = <U_ANTMORPH_DELAY>;
        };
        amennumnwc: am_en_num_nw_c {
            compatible = "zmk,behavior-antecedent-morph";
            label = "AM_EN_NUM_NW_C";
            #binding-cells = <0>;
            defaults = <&none>;
            bindings = <&none>;
            antecedents = <0x070100>;
            max-delay-ms = <U_ANTMORPH_DELAY>;
        };
        amennumnwa: am_en_num_nw_a {
            compatible = "zmk,behavior-antecedent-morph";
            label = "AM_EN_NUM_NW_A";
            #binding-cells = <0>;
            defaults = <&none>;
            bindings = <&none>;
            antecedents = <0x070100>;
            max-delay-ms = <U_ANTMORPH_DELAY>;
        };
        amennumnwg: am_en_num_nw_g {
            compatible = "zmk,behavior-antecedent-morph";
            label = "AM_EN_NUM_NW_G";
            #binding-cells = <0>;
            defaults = <&none>;
            bindings = <&none>;
            antecedents = <0x070100>;
            max-delay-ms = <U_ANTMORPH_DELAY>;
        };
        amennumw: am_en_num_w {
            compatible = "zmk,behavior-antecedent-morph";
            label = "AM_EN_NUM_W";
            #binding-cells = <0>;
            defaults = <&none>;
            bindings = <&none>;
            antecedents = <0x070100>;
            max-delay-ms = <U_ANTMORPH_DELAY>;
        };
        amennumwc: am_en_num_w_c {
            compatible = "zmk,behavior-antecedent-morph";
            label = "AM_EN_NUM_W_C";
            #binding-cells = <0>;
            defaults = <&none>;
            bindings = <&none>;
            antecedents = <0x070100>;
            max-delay-ms = <U_ANTMORPH_DELAY>;
        };
        amennumwa: am_en_num_w_a {
            compatible = "zmk,behavior-antecedent-morph";
            label = "AM_EN_NUM_W_A";
            #binding-cells = <0>;
            defaults = <&none>;
            bindings = <&none>;
            antecedents = <0x070100>;
            max-delay-ms = <U_ANTMORPH_DELAY>;
        };
        amennumwg: am_en_num_w_g {
            compatible = "zmk,behavior-antecedent-morph";
            label = "AM_EN_NUM_W_G";
            #binding-cells = <0>;
            defaults = <&none>;
            bindings = <&none>;
            antecedents = <0x070100>;
            max-delay-ms = <U_ANTMORPH_DELAY>;
        };
        amennumsw: am_en_num_sw {
            compatible = "zmk,behavior-antecedent-morph";
            label = "AM_EN_NUM_SW";
            #binding-cells = <0>;
            defaults = <&none>;
            bindings = <&none>;
            antecedents = <0x070100>;
            max-delay-ms = <U_ANTMORPH_DELAY>;
        };
        amennumswc: am_en_num_sw_c {
            compatible = "zmk,behavior-antecedent-morph";
            label = "AM_EN_NUM_SW_C";
            #binding-cells = <0>;
            defaults = <&none>;
            bindings = <&none>;
            antecedents = <0x070100>;
            max-delay-ms = <U_ANTMORPH_DELAY>;
        };
        amennumswa: am_en_num_sw_a {
            compatible = "zmk,behavior-antecedent-morph";
            label = "AM_EN_NUM_SW_A";
            #binding-cells = <0>;
            defaults = <&none>;
            bindings = <&none>;
            antecedents = <0x070100>;
            max-delay-ms = <U_ANTMORPH_DELAY>;
        };
        amennumswg: am_en_num_sw_g {
            compatible = "zmk,behavior-antecedent-morph";
            label = "AM_EN_NUM_SW_G";
            #binding-cells = <0>;
            defaults = <&none>;
            bindings = <&none>;
            antecedents = <0x070100>;
            max-delay-ms = <U_ANTMORPH_DELAY>;
        };
        amensymnw: am_en_sym_nw {
            compatible = "zmk,behavior-antecedent-morph";
            label = "AM_EN_SYM_NW";
            #binding-cells = <0>;
            defaults = <&none>;
            bindings = <&none>;
            antecedents = <0x070100>;
            max-delay-ms = <U_ANTMORPH_DELAY>;
        };
        amensymnwc: am_en_sym_nw_c {
            compatible = "zmk,behavior-antecedent-morph";
            label = "AM_EN_SYM_NW_C";
            #binding-cells = <0>;
            defaults = <&none>;
            bindings = <&none>;
            antecedents = <0x070100>;
            max-delay-ms = <U_ANTMORPH_DELAY>;
        };
        amensymnwa: am_en_sym_nw_a {
            compatible = "zmk,behavior-antecedent-morph";
            label = "AM_EN_SYM_NW_A";
            #binding-cells = <0>;
            defaults = <&none>;
            bindings = <&none>;
            antecedents = <0x070100>;
            max-delay-ms = <U_ANTMORPH_DELAY>;
        };
        amensymnwg: am_en_sym_nw_g {
            compatible = "zmk,behavior-antecedent-morph";
            label = "AM_EN_SYM_NW_G";
            #binding-cells = <0>;
            defaults = <&none>;
            bindings = <&none>;
            antecedents = <0x070100>;
            max-delay-ms = <U_ANTMORPH_DELAY>;
        };
        amensymw: am_en_sym_w {
            compatible = "zmk,behavior-antecedent-morph";
            label = "AM_EN_SYM_W";
            #binding-cells = <0>;
            defaults = <&none>;
            bindings = <&none>;
            antecedents = <0x070100>;
            max-delay-ms = <U_ANTMORPH_DELAY>;
        };
        amensymwc: am_en_sym_w_c {
            compatible = "zmk,behavior-antecedent-morph";
            label = "AM_EN_SYM_W_C";
            #binding-cells = <0>;
            defaults = <&none>;
            bindings = <&none>;
            antecedents = <0x070100>;
            max-delay-ms = <U_ANTMORPH_DELAY>;
        };
        amensymwa: am_en_sym_w_a {
            compatible = "zmk,behavior-antecedent-morph";
            label = "AM_EN_SYM_W_A";
            #binding-cells = <0>;
            defaults = <&none>;
            bindings = <&none>;
            antecedents = <0x070100>;
            max-delay-ms = <U_ANTMORPH_DELAY>;
        };
        amensymwg: am_en_sym_w_g {
            compatible = "zmk,behavior-antecedent-morph";
            label = "AM_EN_SYM_W_G";
            #binding-cells = <0>;
            defaults = <&none>;
            bindings = <&none>;
            antecedents = <0x070100>;
            max-delay-ms = <U_ANTMORPH_DELAY>;
        };
        amensymsw: am_en_sym_sw {
            compatible = "zmk,behavior-antecedent-morph";
            label = "AM_EN_SYM_SW";
            #binding-cells = <0>;
            defaults = <&none>;
            bindings = <&none>;
            antecedents = <0x070100>;
            max-delay-ms = <U_ANTMORPH_DELAY>;
        };
        amensymswc: am_en_sym_sw_c {
            compatible = "zmk,behavior-antecedent-morph";
            label = "AM_EN_SYM_SW_C";
            #binding-cells = <0>;
            defaults = <&none>;
            bindings = <&none>;
            antecedents = <0x070100>;
            max-delay-ms = <U_ANTMORPH_DELAY>;
        };
        amensymswa: am_en_sym_sw_a {
            compatible = "zmk,behavior-antecedent-morph";
            label = "AM_EN_SYM_SW_A";
            #binding-cells = <0>;
            defaults = <&none>;
            bindings = <&none>;
            antecedents = <0x070100>;
            max-delay-ms = <U_ANTMORPH_DELAY>;
        };
        amensymswg: am_en_sym_sw_g {
            compatible = "zmk,behavior-antecedent-morph";
            label = "AM_EN_SYM_SW_G";
            #binding-cells = <0>;
            defaults = <&none>;
            bindings = <&none>;
            antecedents = <0x070100>;
            max-delay-ms = <U_ANTMORPH_DELAY>;
        };
    };
    macros {
        // 'P'
        amen_proostas: amen_proostas {
            compatible = "zmk,behavior-macro";
            #binding-cells = <0>;
            wait-ms = <U_ANTMORPH_MACRO_WAIT>;
            tap-ms = <U_ANTMORPH_MACRO_TAP>;
            // (p)roostas
            bindings = <&macro_tap &kp R &kp O &kp O &kp S &kp T &kp A &kp S>;
        };
        // '1'
        amen_monday: amen_monday {
            compatible = "zmk,behavior-macro";
            #binding-cells = <0>;
            wait-ms = <U_ANTMORPH_MACRO_WAIT>;
            tap-ms = <U_ANTMORPH_MACRO_TAP>;
            // [1]Monday
            bindings = <&macro_tap &kp BSPC &kp LS(M) &kp O &kp N &kp D &kp A &kp Y>;
        };
        // '2'
        amen_tuesday: amen_tuesday {
            compatible = "zmk,behavior-macro";
            #binding-cells = <0>;
            wait-ms = <U_ANTMORPH_MACRO_WAIT>;
            tap-ms = <U_ANTMORPH_MACRO_TAP>;
            // [2]Tuesday
            bindings = <&macro_tap &kp BSPC &kp LS(T) &kp U &kp E &kp S &kp D &kp A &kp Y>;
        };
        // '3'
        amen_wednesday: amen_wednesday {
            compatible = "zmk,behavior-macro";
            #binding-cells = <0>;
            wait-ms = <U_ANTMORPH_MACRO_WAIT>;
            tap-ms = <U_ANTMORPH_MACRO_TAP>;
            // [3]Wednesday
            bindings = <&macro_tap &kp BSPC &kp LS(W) &kp E &kp D &kp N &kp E &kp S &kp D &kp A &kp Y>;
        };
        // '4'
        amen_thursday: amen_thursday {
            compatible = "zmk,behavior-macro";
            #binding-cells = <0>;
            wait-ms = <U_ANTMORPH_MACRO_WAIT>;
            tap-ms = <U_ANTMORPH_MACRO_TAP>;
            // [4]Thursday
            bindings = <&macro_tap &kp BSPC &kp LS(T) &kp H &kp U &kp R &kp S &kp D &kp A &kp Y>;
        };
        // '5'
        amen_friday: amen_friday {
            compatible = "zmk,behavior-macro";
            #binding-cells = <0>;
            wait-ms = <U_ANTMORPH_MACRO_WAIT>;
            tap-ms = <U_ANTMORPH_MACRO_TAP>;
            // [5]Friday
            bindings = <&macro_tap &kp BSPC &kp LS(F) &kp R &kp I &kp D &kp A &kp Y>;
        };
        // '6'
        amen_saturday: amen_saturday {
            compatible = "zmk,behavior-macro";
            #binding-cells = <0>;
            wait-ms = <U_ANTMORPH_MACRO_WAIT>;
            tap-ms = <U_ANTMORPH_MACRO_TAP>;
            // [6]Saturday
            bindings = <&macro_tap &kp BSPC &kp LS(S) &kp A &kp T &kp U &kp R &kp D &kp A &kp Y>;
        };
        // '7'
        amen_sunday: amen_sunday {
            compatible = "zmk,behavior-macro";
            #binding-cells = <0>;
            wait-ms = <U_ANTMORPH_MACRO_WAIT>;
            tap-ms = <U_ANTMORPH_MACRO_TAP>;
            // [7]Sunday
            bindings = <&macro_tap &kp BSPC &kp LS(S) &kp U &kp N &kp D &kp A &kp Y>;
        };
        // '@'
        amen_prokofyevme: amen_prokofyevme {
            compatible = "zmk,behavior-macro";
            #binding-cells = <0>;
            wait-ms = <U_ANTMORPH_MACRO_WAIT>;
            tap-ms = <U_ANTMORPH_MACRO_TAP>;
            // (@)prokofyev.me
            bindings = <&macro_tap &kp P &kp R &kp O &kp K &kp O &kp F &kp Y &kp E &kp V &kp DOT &kp M &kp E>;
        };
        amen_yandexru: amen_yandexru {
            compatible = "zmk,behavior-macro";
            #binding-cells = <0>;
            wait-ms = <U_ANTMORPH_MACRO_WAIT>;
            tap-ms = <U_ANTMORPH_MACRO_TAP>;
            // (@)yandex.ru
            bindings = <&macro_tap &kp Y &kp A &kp N &kp D &kp E &kp X &kp DOT &kp R &kp U>;
        };
        amen_gmailcom: amen_gmailcom {
            compatible = "zmk,behavior-macro";
            #binding-cells = <0>;
            wait-ms = <U_ANTMORPH_MACRO_WAIT>;
            tap-ms = <U_ANTMORPH_MACRO_TAP>;
            // (@)gmail.com
            bindings = <&macro_tap &kp G &kp M &kp A &kp I &kp L &kp DOT &kp C &kp O &kp M>;
        };
        // ' '
        amen_english_v20: amen_english_v20 {
            compatible = "zmk,behavior-macro";
            #binding-cells = <0>;
            wait-ms = <U_ANTMORPH_MACRO_WAIT>;
            tap-ms = <U_ANTMORPH_MACRO_TAP>;
            // [ ]English v2.0
            bindings = <&macro_tap &kp BSPC &kp LS(E) &kp N &kp G &kp L &kp I &kp S &kp H &kp SPACE &kp V &kp N2 &kp DOT &kp N0>;
        };
    };
};
